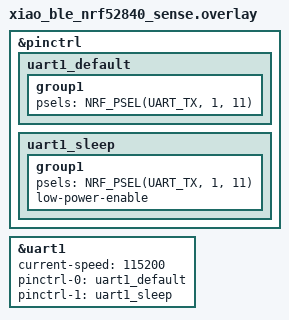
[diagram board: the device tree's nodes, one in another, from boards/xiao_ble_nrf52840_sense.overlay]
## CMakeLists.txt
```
cmake_minimum_required(VERSION 3.20.0)

find_package(Zephyr REQUIRED HINTS $ENV{ZEPHYR_BASE})
project(base_node)

target_sources(app PRIVATE
    src/main.c
    src/processing_thread.c
    src/imu.c
    src/fusion.c
    src/zupt.c
    src/radius.c
    src/tracker_pose.pb.c
    src/ble_pose.c
)
zephyr_include_directories(
    inc
    ../inc
)

target_link_libraries(app PRIVATE m)
```

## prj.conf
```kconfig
CONFIG_STDOUT_CONSOLE=y
CONFIG_UART_CONSOLE=y
CONFIG_SERIAL=y
CONFIG_GPIO=y
# nanopb needs these
CONFIG_NANOPB=y
CONFIG_BT=y
CONFIG_BT_PERIPHERAL=y
CONFIG_BT_DEVICE_NAME="TrackerPose"
CONFIG_BT_MAX_CONN=1
# UART for TX to ESP32-CAM
CONFIG_UART_INTERRUPT_DRIVEN=n
CONFIG_SERIAL=y
# Sensor stack — LSM6DS3TR-C IMU is wired in the XIAO BLE Sense board DTS
# with compatible "st,lsm6dsl"; the lsm6dsl driver handles it.
CONFIG_I2C=y
CONFIG_SENSOR=y
CONFIG_LSM6DSL=y

CONFIG_CBPRINTF_FP_SUPPORT=y
CONFIG_FPU=y

# USB CDC-ACM console is wired by the XIAO BLE board defconfig
# (USB_DEVICE_STACK_NEXT=y + CDC_ACM_SERIAL_INITIALIZE_AT_BOOT=y). Do NOT also
# enable CONFIG_USB_DEVICE_STACK — that links the legacy cdc_acm driver and
# collides with the new-stack one on the same DT node.

CONFIG_LOG=y
CONFIG_LOG_DEFAULT_LEVEL=2
CONFIG_BT=y
CONFIG_BT_PERIPHERAL=y
CONFIG_BT_DEVICE_NAME="TrackerPose"
```

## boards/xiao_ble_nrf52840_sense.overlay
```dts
/*
 * boards/xiao_ble_sense.overlay   (or xiao_ble.overlay — match your board name)
 */

&pinctrl {
    uart1_default: uart1_default {
        group1 {
            /* TX only — we don't need RX from ESP32-CAM */
            psels = <NRF_PSEL(UART_TX, 1, 11)>;  /* P0.06 — adjust to your wiring */
        };
    };

    uart1_sleep: uart1_sleep {
        group1 {
            psels = <NRF_PSEL(UART_TX, 1, 11)>;
            low-power-enable;
        };
    };
};

&uart1 {
    status = "okay";
    current-speed = <115200>;
    pinctrl-0 = <&uart1_default>;
    pinctrl-1 = <&uart1_sleep>;
    pinctrl-names = "default", "sleep";
};
```

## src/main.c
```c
#include <zephyr/kernel.h>
#include "processing_thread.h"

// Thread defines
#define PROC_THREAD_STACK_SIZE  8192
#define PROC_THREAD_PRIORITY    5

K_THREAD_STACK_DEFINE(proc_thread_stack, PROC_THREAD_STACK_SIZE);
static struct k_thread proc_thread_data;


int main(void)
{
    /* Give the host a moment to enumerate USB CDC-ACM before we start
     * emitting LOCATION lines, otherwise the first few are dropped. */
    k_msleep(2000);

    printk("Tracker starting\n");

    k_thread_create(&proc_thread_data,
                    proc_thread_stack,
                    K_THREAD_STACK_SIZEOF(proc_thread_stack),
                    processing_thread_entry,
                    NULL, NULL, NULL,
                    PROC_THREAD_PRIORITY, 0, K_NO_WAIT);
    k_thread_name_set(&proc_thread_data, "processing");
    return 0;
}
```

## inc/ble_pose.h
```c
#pragma once
#include <stdbool.h>
#include <stdint.h>

void ble_pose_init(void);
void ble_pose_update(float pitch_deg, uint32_t frame_index);
```

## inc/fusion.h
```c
#ifndef PURPLE_RHEA_FUSION_H
#define PURPLE_RHEA_FUSION_H

void fusion_init(void);

/* gyro in rad/s, accel in any consistent unit (only direction matters). */
void fusion_update(float gx, float gy, float gz,
		   float ax, float ay, float az,
		   float dt);

/* Output Euler angles in degrees (roll, pitch, yaw, ZYX convention). */
void fusion_get_euler(float *roll, float *pitch, float *yaw);

/* Output unit quaternion (w, x, y, z) representing body-to-world rotation. */
void fusion_get_quaternion(float q[4]);

/* Force yaw to zero at the current orientation (rotates the reference frame
 * about gravity). Use at scan start with the arm at the 0° position. */
void fusion_zero_yaw(void);

#endif
```

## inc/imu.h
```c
#ifndef PURPLE_RHEA_IMU_H
#define PURPLE_RHEA_IMU_H

#include <stdbool.h>

int imu_init(void);

/* Returns 0 on success. accel in m/s^2, gyro in rad/s. */
int imu_read(float accel[3], float gyro[3]);

#endif
```

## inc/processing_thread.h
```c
#ifndef PROCESSING_THREAD_H
#define PROCESSING_THREAD_H
#include <stdbool.h>
#include <zephyr/kernel.h>

void processing_thread_entry(void *p1, void *p2, void *p3);
#endif
```

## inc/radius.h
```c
#ifndef PURPLE_RHEA_RADIUS_H
#define PURPLE_RHEA_RADIUS_H

#include <stdbool.h>

void radius_init(void);

/* Feed one IMU tick after gyro-bias correction.
 *
 *   q          body-to-world quaternion (w, x, y, z) from fusion
 *   accel_body raw accel in m/s^2, body frame
 *   gyro_body  bias-corrected gyro in rad/s, body frame
 *   dt         tick period in seconds
 *
 * Internally: rotate accel and gyro into world frame, subtract gravity from
 * world-frame accel, accumulate (omega^2, |a_horiz|) for weighted least
 * squares. Samples are gated on |omega| > omega_min and steady rotation.
 */
void radius_feed(const float q[4],
		 const float accel_body[3],
		 const float gyro_body[3],
		 float dt);

/* Latest estimate. Returns true and writes r in metres if enough samples
 * have accumulated; false if not yet converged. */
bool radius_estimate(float *r_out);

/* Diagnostic snapshot — last accepted (omega_z, a_horiz) and accumulated
 * weight. Useful for debugging why the estimator isn't converging. */
void radius_status(float *omega_z, float *a_horiz, float *weight);

#endif
```

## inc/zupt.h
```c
#ifndef PURPLE_RHEA_ZUPT_H
#define PURPLE_RHEA_ZUPT_H

#include <stdbool.h>

void zupt_init(void);

/* Feed every IMU sample (raw accel + raw gyro in body frame, m/s^2 and rad/s).
 * Updates the still-detector and, when still, tracks a low-passed gyro bias. */
void zupt_feed(float ax, float ay, float az,
	       float gx, float gy, float gz,
	       float dt);

bool zupt_is_still(void);

/* Latest gyro-bias estimate in rad/s. Subtract from raw gyro before fusion. */
void zupt_get_bias(float bias[3]);

#endif
```

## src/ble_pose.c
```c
#include "ble_pose.h"

#include <zephyr/bluetooth/bluetooth.h>
#include <zephyr/bluetooth/gatt.h>
#include <zephyr/bluetooth/uuid.h>
#include <zephyr/logging/log.h>

#include "tracker_pose.pb.h"
#include <pb_encode.h>

LOG_MODULE_REGISTER(ble_pose, LOG_LEVEL_INF);

#define BT_UUID_POSE_SVC_VAL \
    BT_UUID_128_ENCODE(0x12345678, 0x1234, 0x5678, 0x1234, 0x56789abcdef0)
#define BT_UUID_POSE_CHR_VAL \
    BT_UUID_128_ENCODE(0x12345678, 0x1234, 0x5678, 0x1234, 0x56789abcdef1)

static struct bt_uuid_128 pose_svc_uuid = BT_UUID_INIT_128(BT_UUID_POSE_SVC_VAL);
static struct bt_uuid_128 pose_chr_uuid = BT_UUID_INIT_128(BT_UUID_POSE_CHR_VAL);

extern const struct bt_gatt_service_static pose_svc;
static bool notify_enabled = false;

static void ccc_changed(const struct bt_gatt_attr *attr, uint16_t value)
{
    notify_enabled = (value == BT_GATT_CCC_NOTIFY);
    LOG_INF("pose notify %s", notify_enabled ? "enabled" : "disabled");
}

BT_GATT_SERVICE_DEFINE(pose_svc,
    BT_GATT_PRIMARY_SERVICE(&pose_svc_uuid),
    BT_GATT_CHARACTERISTIC(&pose_chr_uuid.uuid,
                           BT_GATT_CHRC_NOTIFY,
                           BT_GATT_PERM_NONE,
                           NULL, NULL, NULL),
    BT_GATT_CCC(ccc_changed, BT_GATT_PERM_READ | BT_GATT_PERM_WRITE),
);

static const struct bt_data ad[] = {
    BT_DATA_BYTES(BT_DATA_FLAGS, BT_LE_AD_GENERAL | BT_LE_AD_NO_BREDR),
    BT_DATA_BYTES(BT_DATA_UUID128_ALL, BT_UUID_POSE_SVC_VAL),
};

static const struct bt_data sd[] = {
    BT_DATA(BT_DATA_NAME_COMPLETE, "TrackerPose", sizeof("TrackerPose") - 1),
};

void ble_pose_init(void)
{
    int err = bt_enable(NULL);
    if (err) {
        LOG_ERR("bt_enable failed: %d", err);
        return;
    }
    err = bt_le_adv_start(BT_LE_ADV_CONN_FAST_1, ad, ARRAY_SIZE(ad),
                          sd, ARRAY_SIZE(sd));
    if (err) {
        LOG_ERR("adv_start failed: %d", err);
        return;
    }
    LOG_INF("BLE advertising as 'TrackerPose'");
}

/* Called from processing_thread at 20 Hz — encodes and notifies immediately */
void ble_pose_update(float pitch_deg, uint32_t frame_index)
{
    if (!notify_enabled) return;

    TrackerPose msg = TrackerPose_init_zero;
    msg.pitch       = pitch_deg;
    msg.frame_index = frame_index;

    uint8_t buf[TrackerPose_size];
    pb_ostream_t stream = pb_ostream_from_buffer(buf, sizeof(buf));
    if (!pb_encode(&stream, TrackerPose_fields, &msg)) {
        LOG_ERR("pb_encode failed");
        return;
    }
    bt_gatt_notify(NULL, &pose_svc.attrs[2], buf, stream.bytes_written);
}
```

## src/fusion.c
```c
/* Mahony 6-axis (accel + gyro) complementary filter.
 *
 * Reference: Mahony, Hamel, Pflimlin, "Nonlinear Complementary Filters on the
 * Special Orthogonal Group" (2008). 6-axis version: only the gravity vector
 * is used to correct roll/pitch; yaw drifts open-loop and must be zeroed at
 * a known reference (see fusion_zero_yaw). */

#include "fusion.h"

#include <math.h>

#define TWO_KP (2.0f * 1.5f)   /* proportional gain — tune per IMU noise */
#define TWO_KI (2.0f * 0.005f) /* integral gain — small to reject bias drift */

static float q0 = 1.0f, q1 = 0.0f, q2 = 0.0f, q3 = 0.0f;
static float ix, iy, iz;

static float inv_sqrt(float x)
{
	return 1.0f / sqrtf(x);
}

void fusion_init(void)
{
	q0 = 1.0f;
	q1 = q2 = q3 = 0.0f;
	ix = iy = iz = 0.0f;
}

void fusion_update(float gx, float gy, float gz,
		   float ax, float ay, float az,
		   float dt)
{
	float norm = ax * ax + ay * ay + az * az;
	if (norm > 0.0f) {
		float recip = inv_sqrt(norm);
		ax *= recip;
		ay *= recip;
		az *= recip;

		/* Estimated gravity direction from current attitude */
		float vx = 2.0f * (q1 * q3 - q0 * q2);
		float vy = 2.0f * (q0 * q1 + q2 * q3);
		float vz = q0 * q0 - q1 * q1 - q2 * q2 + q3 * q3;

		/* Error is cross product between measured and estimated gravity */
		float ex = (ay * vz - az * vy);
		float ey = (az * vx - ax * vz);
		float ez = (ax * vy - ay * vx);

		if (TWO_KI > 0.0f) {
			ix += TWO_KI * ex * dt;
			iy += TWO_KI * ey * dt;
			iz += TWO_KI * ez * dt;
			gx += ix;
			gy += iy;
			gz += iz;
		}

		gx += TWO_KP * ex;
		gy += TWO_KP * ey;
		gz += TWO_KP * ez;
	}

	gx *= 0.5f * dt;
	gy *= 0.5f * dt;
	gz *= 0.5f * dt;

	float qa = q0, qb = q1, qc = q2;
	q0 += (-qb * gx - qc * gy - q3 * gz);
	q1 += ( qa * gx + qc * gz - q3 * gy);
	q2 += ( qa * gy - qb * gz + q3 * gx);
	q3 += ( qa * gz + qb * gy - qc * gx);

	float recip = inv_sqrt(q0 * q0 + q1 * q1 + q2 * q2 + q3 * q3);
	q0 *= recip;
	q1 *= recip;
	q2 *= recip;
	q3 *= recip;
}

void fusion_get_euler(float *roll, float *pitch, float *yaw)
{
	const float rad2deg = 57.29577951308232f;
	*roll  = atan2f(2.0f * (q0 * q1 + q2 * q3),
			1.0f - 2.0f * (q1 * q1 + q2 * q2)) * rad2deg;
	float sinp = 2.0f * (q0 * q2 - q3 * q1);
	if (sinp > 1.0f)  sinp = 1.0f;
	if (sinp < -1.0f) sinp = -1.0f;
	*pitch = asinf(sinp) * rad2deg;
	*yaw   = atan2f(2.0f * (q0 * q3 + q1 * q2),
			1.0f - 2.0f * (q2 * q2 + q3 * q3)) * rad2deg;
}

void fusion_get_quaternion(float q[4])
{
	q[0] = q0;
	q[1] = q1;
	q[2] = q2;
	q[3] = q3;
}

void fusion_zero_yaw(void)
{
	/* Rotate current attitude by -current_yaw about world Z. Compose
	 * q' = q_yaw_inv * q, where q_yaw_inv is rotation by -yaw about Z. */
	float yaw_rad = atan2f(2.0f * (q0 * q3 + q1 * q2),
			       1.0f - 2.0f * (q2 * q2 + q3 * q3));
	float half = -0.5f * yaw_rad;
	float cw = cosf(half);
	float sw = sinf(half);
	/* q_yaw_inv = (cw, 0, 0, sw) */
	float n0 = cw * q0 - sw * q3;
	float n1 = cw * q1 - sw * q2;
	float n2 = cw * q2 + sw * q1;
	float n3 = cw * q3 + sw * q0;
	q0 = n0; q1 = n1; q2 = n2; q3 = n3;
}
```

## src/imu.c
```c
#include "imu.h"

#include <zephyr/device.h>
#include <zephyr/drivers/sensor.h>
#include <zephyr/logging/log.h>

LOG_MODULE_REGISTER(imu, LOG_LEVEL_INF);

/* LSM6DS3TR-C on XIAO BLE Sense is declared with compatible "st,lsm6dsl" in
 * the board DTS, so DEVICE_DT_GET_ONE(st_lsm6dsl) resolves to it. */
static const struct device *imu_dev;

int imu_init(void)
{
	imu_dev = DEVICE_DT_GET_ONE(st_lsm6dsl);
	if (!device_is_ready(imu_dev)) {
		LOG_ERR("lsm6dsl not ready");
		return -ENODEV;
	}

	struct sensor_value odr = { .val1 = 104, .val2 = 0 };

	if (sensor_attr_set(imu_dev, SENSOR_CHAN_ACCEL_XYZ,
			    SENSOR_ATTR_SAMPLING_FREQUENCY, &odr) < 0) {
		LOG_ERR("set accel ODR failed");
		return -EIO;
	}
	if (sensor_attr_set(imu_dev, SENSOR_CHAN_GYRO_XYZ,
			    SENSOR_ATTR_SAMPLING_FREQUENCY, &odr) < 0) {
		LOG_ERR("set gyro ODR failed");
		return -EIO;
	}

	LOG_INF("IMU ready @ 104 Hz");
	return 0;
}

int imu_read(float accel[3], float gyro[3])
{
	struct sensor_value v[3];

	if (sensor_sample_fetch(imu_dev) < 0) {
		return -EIO;
	}

	if (sensor_channel_get(imu_dev, SENSOR_CHAN_ACCEL_XYZ, v) < 0) {
		return -EIO;
	}
	accel[0] = (float)sensor_value_to_double(&v[0]);
	accel[1] = (float)sensor_value_to_double(&v[1]);
	accel[2] = (float)sensor_value_to_double(&v[2]);

	if (sensor_channel_get(imu_dev, SENSOR_CHAN_GYRO_XYZ, v) < 0) {
		return -EIO;
	}
	gyro[0] = (float)sensor_value_to_double(&v[0]);
	gyro[1] = (float)sensor_value_to_double(&v[1]);
	gyro[2] = (float)sensor_value_to_double(&v[2]);

	return 0;
}
```

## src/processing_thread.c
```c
#include "processing_thread.h"

#include "imu.h"
#include "fusion.h"
#include "zupt.h"
#include "radius.h"
#include "tracker_pose.pb.h"
#include <pb_encode.h>
#include <zephyr/drivers/uart.h>
#include <stdio.h>
#include <string.h>
#include <zephyr/kernel.h>
#include <zephyr/logging/log.h>

LOG_MODULE_REGISTER(processing, LOG_LEVEL_INF);

/* 104 Hz IMU sample → fusion + ZUPT, 20 Hz LOCATION emission on CDC console.
 * Yaw auto-zeroes the first time the rig is held still after a short settle. */

#define SAMPLE_HZ        104
#define SAMPLE_PERIOD_MS (1000 / SAMPLE_HZ)
#define EMIT_EVERY_N     5   /* 104/5 ≈ 20 Hz LOCATION emission */
#define SETTLE_TICKS     (SAMPLE_HZ * 2)   /* wait 2 s before allowing auto-zero */



void processing_thread_entry(void *p1, void *p2, void *p3)
{
    ARG_UNUSED(p1); ARG_UNUSED(p2); ARG_UNUSED(p3);
    k_msleep(3000);

    if (imu_init() != 0) {
        LOG_ERR("imu_init failed — thread exiting");
        return;
    }

    ble_pose_init();
    printk("STATUS:ready\n");

    uint32_t frame_index = 0;

    while (true) {
        k_msleep(50);  /* 20 Hz */

        float a[3], g[3];
        if (imu_read(a, g) != 0) {
            LOG_WRN("imu_read failed");
            continue;
        }

        /* a[] is [x, y, z] in sensor frame.
         * Define pitch_deg as the angle of the USB axis from horizontal.
         * 0°  = USB pointing horizontally away from centre
         * 90° = USB pointing straight down at ground
         * Adjust axis sign/index to match your board orientation. */
        float ax = a[0], ay = a[1], az = a[2];
        float horiz = sqrtf(ax * ax + ay * ay);
        float pitch_deg = atan2f(-az, horiz) * (180.0f / (float)M_PI);

        ble_pose_update(pitch_deg, frame_index++);
    }
}
```

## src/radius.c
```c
/* Online weighted least-squares estimator for the orbit radius of a rigid
 * arm spinning about a vertical axis.
 *
 * Physics: a point at radius r from the rotation axis spinning at angular
 * velocity ω experiences centripetal acceleration of magnitude ω²·r in the
 * horizontal plane, pointed at the axis. Given the fusion's body-to-world
 * quaternion we can rotate the body-frame accel into the world frame,
 * subtract gravity, and use the magnitude of the horizontal residual.
 *
 * Likewise, the gyro vector rotated into the world frame gives the angular
 * velocity about world-Z directly — independent of how the IMU is mounted.
 *
 * Weighted LSQ slope through origin: y_i = a_horiz_i, x_i = ω_z_world².
 *   r̂ = Σ(x_i · y_i) / Σ(x_i²)
 * Exponentially-weighted accumulators give a slowly-adapting estimate. */

#include "radius.h"

#include <math.h>

#define GRAVITY        9.80665f
#define OMEGA_MIN      0.15f     /* rad/s — ~8.6°/s, comfortable hand-spin */
#define DOMEGA_MAX     15.0f     /* rad/s² — reject only large tangential spikes */
#define TAU_S          5.0f      /* averaging time constant */
#define MIN_WEIGHT_SUM 0.05f     /* Σω⁴ threshold to publish an estimate */

static float s_xy;             /* Σ ω² · a_horiz */
static float s_xx;             /* Σ ω⁴ */
static float prev_omega_z;
static bool  prev_omega_valid;
static float last_omega_z;     /* most recent ω (any value, ungated) */
static float last_a_horiz;

void radius_init(void)
{
	s_xy = 0.0f;
	s_xx = 0.0f;
	prev_omega_z = 0.0f;
	prev_omega_valid = false;
	last_omega_z = 0.0f;
	last_a_horiz = 0.0f;
}

/* Rotate a body-frame vector v into the world frame using unit quaternion q
 * (w, x, y, z). Uses v' = v + 2·w·(q_vec × v) + 2·(q_vec × (q_vec × v)). */
static void rotate_body_to_world(const float q[4], const float v[3], float out[3])
{
	float w = q[0], x = q[1], y = q[2], z = q[3];

	float tx = 2.0f * (y * v[2] - z * v[1]);
	float ty = 2.0f * (z * v[0] - x * v[2]);
	float tz = 2.0f * (x * v[1] - y * v[0]);

	out[0] = v[0] + w * tx + (y * tz - z * ty);
	out[1] = v[1] + w * ty + (z * tx - x * tz);
	out[2] = v[2] + w * tz + (x * ty - y * tx);
}

void radius_feed(const float q[4],
		 const float accel_body[3],
		 const float gyro_body[3],
		 float dt)
{
	float a_world[3];
	float g_world[3];
	rotate_body_to_world(q, accel_body, a_world);
	rotate_body_to_world(q, gyro_body, g_world);

	/* Subtract gravity in world frame. */
	a_world[2] -= GRAVITY;

	float omega_z = g_world[2];
	float a_horiz = sqrtf(a_world[0] * a_world[0] + a_world[1] * a_world[1]);

	last_omega_z = omega_z;
	last_a_horiz = a_horiz;

	/* Gate: need sustained, steady spin. */
	if (fabsf(omega_z) < OMEGA_MIN) {
		prev_omega_valid = false;
		return;
	}
	if (prev_omega_valid) {
		float domega = (omega_z - prev_omega_z) / dt;
		if (fabsf(domega) > DOMEGA_MAX) {
			prev_omega_z = omega_z;
			return;
		}
	}
	prev_omega_z = omega_z;
	prev_omega_valid = true;

	/* Exponential weighting: each new sample contributes (1 - α). */
	float alpha = expf(-dt / TAU_S);
	float x = omega_z * omega_z;

	s_xy = alpha * s_xy + (1.0f - alpha) * (x * a_horiz);
	s_xx = alpha * s_xx + (1.0f - alpha) * (x * x);
}

bool radius_estimate(float *r_out)
{
	if (s_xx < MIN_WEIGHT_SUM) {
		return false;
	}
	float r = s_xy / s_xx;
	if (!isfinite(r) || r < 0.0f) {
		return false;
	}
	*r_out = r;
	return true;
}

void radius_status(float *omega_z, float *a_horiz, float *weight)
{
	if (omega_z) *omega_z = last_omega_z;
	if (a_horiz) *a_horiz = last_a_horiz;
	if (weight)  *weight  = s_xx;
}
```

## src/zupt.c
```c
/* Zero-velocity update detector + gyro-bias estimator.
 *
 * Detector: ring buffer of recent accel-norm samples; if peak-to-peak stays
 * within a tight window AND mean is near 1 g for a sustained period, we are
 * "still". While still, gyro readings are low-pass-filtered into the bias
 * estimate. */

#include "zupt.h"

#include <math.h>

#define WINDOW       32      /* ~0.31 s at 104 Hz */
#define G_MIN        9.4f
#define G_MAX        10.2f
#define P2P_THRESH   0.35f   /* m/s^2 — accel magnitude variation while still */
#define BIAS_TAU_S   0.5f    /* bias low-pass time constant */

static float ring[WINDOW];
static int ring_idx;
static int ring_filled;

static float bias_x, bias_y, bias_z;
static bool still;

void zupt_init(void)
{
	ring_idx = 0;
	ring_filled = 0;
	bias_x = bias_y = bias_z = 0.0f;
	still = false;
	for (int i = 0; i < WINDOW; i++) {
		ring[i] = 0.0f;
	}
}

void zupt_feed(float ax, float ay, float az,
	       float gx, float gy, float gz,
	       float dt)
{
	float norm = sqrtf(ax * ax + ay * ay + az * az);
	ring[ring_idx] = norm;
	ring_idx = (ring_idx + 1) % WINDOW;
	if (ring_filled < WINDOW) {
		ring_filled++;
	}

	if (ring_filled < WINDOW) {
		still = false;
		return;
	}

	float lo = ring[0], hi = ring[0], sum = 0.0f;
	for (int i = 0; i < WINDOW; i++) {
		float v = ring[i];
		if (v < lo) lo = v;
		if (v > hi) hi = v;
		sum += v;
	}
	float mean = sum / (float)WINDOW;

	still = ((hi - lo) < P2P_THRESH) && (mean > G_MIN) && (mean < G_MAX);

	if (still) {
		/* Exponential low-pass towards current gyro reading. */
		float alpha = dt / (BIAS_TAU_S + dt);
		bias_x += alpha * (gx - bias_x);
		bias_y += alpha * (gy - bias_y);
		bias_z += alpha * (gz - bias_z);
	}
}

bool zupt_is_still(void)
{
	return still;
}

void zupt_get_bias(float bias[3])
{
	bias[0] = bias_x;
	bias[1] = bias_y;
	bias[2] = bias_z;
}
```
